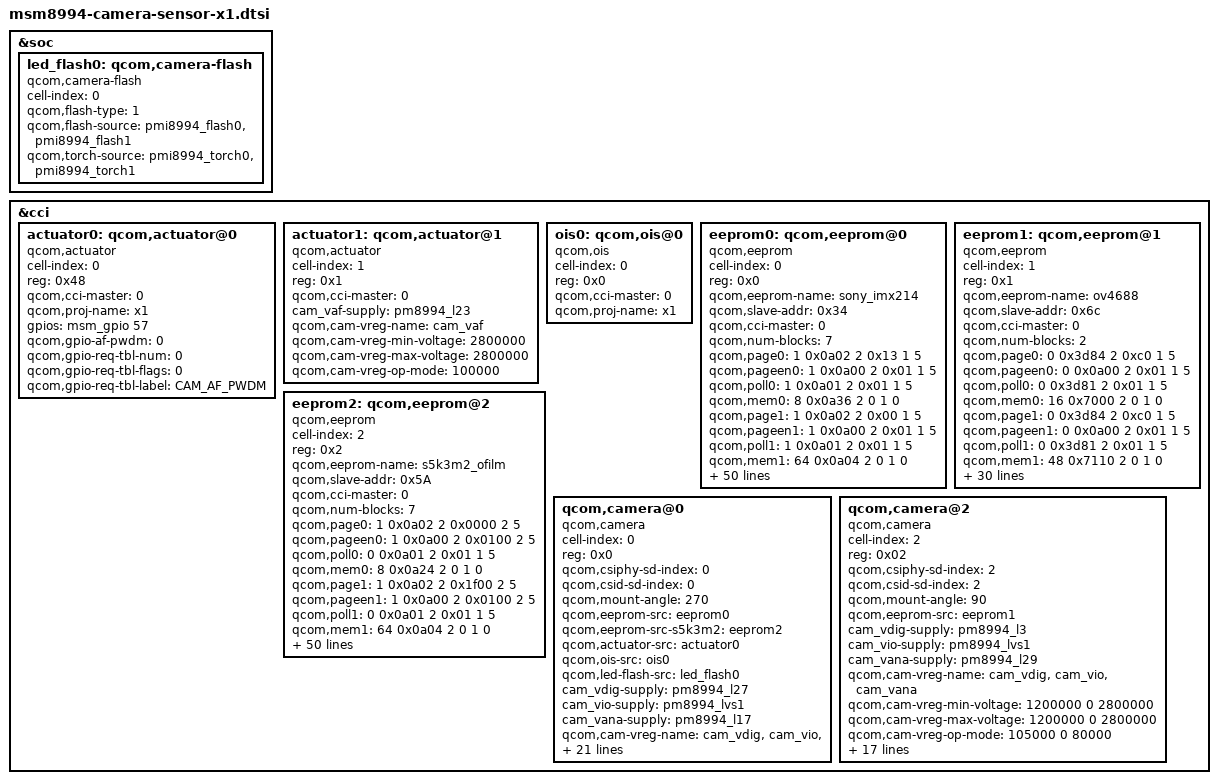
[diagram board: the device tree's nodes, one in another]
/*
 * Copyright (c) 2014, The Linux Foundation. All rights reserved.
 *
 * This program is free software; you can redistribute it and/or modify
 * it under the terms of the GNU General Public License version 2 and
 * only version 2 as published by the Free Software Foundation.
 *
 * This program is distributed in the hope that it will be useful,
 * but WITHOUT ANY WARRANTY; without even the implied warranty of
 * MERCHANTABILITY or FITNESS FOR A PARTICULAR PURPOSE.  See the
 * GNU General Public License for more details.
 */

&soc {
	led_flash0: qcom,camera-flash {
		cell-index = <0>;
		compatible = "qcom,camera-flash";
		qcom,flash-type = <1>;
		qcom,flash-source = <&pmi8994_flash0 &pmi8994_flash1>;
		qcom,torch-source = <&pmi8994_torch0 &pmi8994_torch1>;
	};
};

&cci {
	actuator0: qcom,actuator@0 {
		cell-index = <0>;
		reg = <0x48>;
		compatible = "qcom,actuator";
		qcom,cci-master = <0>;
		qcom,proj-name = "x1";
		gpios = <&msm_gpio 57 0>;
		qcom,gpio-af-pwdm = <0>;
		qcom,gpio-req-tbl-num = <0>;
		qcom,gpio-req-tbl-flags = <0>;
		qcom,gpio-req-tbl-label =  "CAM_AF_PWDM";
	};

	actuator1: qcom,actuator@1 {
		cell-index = <1>;
		reg = <0x1>;
		compatible = "qcom,actuator";
		qcom,cci-master = <0>;
		cam_vaf-supply = <&pm8994_l23>;
		qcom,cam-vreg-name = "cam_vaf";
		qcom,cam-vreg-min-voltage = <2800000>;
		qcom,cam-vreg-max-voltage = <2800000>;
		qcom,cam-vreg-op-mode = <100000>;
	};


	ois0: qcom,ois@0 {
		cell-index = <0>;
		reg = <0x0>;
		compatible = "qcom,ois";
		qcom,cci-master = <0>;
		qcom,proj-name = "x1";
		/*
		cam_vaf-supply = <&pm8994_l23>;
		qcom,cam-vreg-name = "cam_vaf";
		qcom,cam-vreg-min-voltage = <2800000>;
		qcom,cam-vreg-max-voltage = <2800000>;
		qcom,cam-vreg-op-mode = <100000>;
		*/
	};

	eeprom0: qcom,eeprom@0 {
		cell-index = <0>;
		reg = <0x0>;
		qcom,eeprom-name = "sony_imx214";
		compatible = "qcom,eeprom";
		qcom,slave-addr = <0x34>;
		qcom,cci-master = <0>;
		qcom,num-blocks = <7>;
		qcom,page0 = <1 0x0a02 2 0x13 1 5>;
		qcom,pageen0 = <1 0x0a00 2 0x01 1 5>;
		qcom,poll0 = <1 0x0a01 2 0x01 1 5>;
		qcom,mem0 = <8 0x0a36 2 0 1 0>;

		qcom,page1 = <1 0x0a02 2 0x00 1 5>;
		qcom,pageen1 = <1 0x0a00 2 0x01 1 5>;
		qcom,poll1 = <1 0x0a01 2 0x01 1 5>;
		qcom,mem1 = <64 0x0a04 2 0 1 0>;

		qcom,page2 = <1 0x0a02 2 0x01 1 5>;
		qcom,pageen2 = <1 0x0a00 2 0x01 1 5>;
		qcom,poll2 = <1 0x0a01 2 0x01 1 5>;
		qcom,mem2 = <64 0x0a04 2 0 1 0>;

		qcom,page3 = <1 0x0a02 2 0x02 1 5>;
		qcom,pageen3 = <1 0x0a00 2 0x01 1 5>;
		qcom,poll3 = <1 0x0a01 2 0x01 1 5>;
		qcom,mem3 = <64 0x0a04 2 0 1 0>;

		qcom,page4 = <1 0x0a02 2 0x03 1 5>;
		qcom,pageen4 = <1 0x0a00 2 0x01 1 5>;
		qcom,poll4 = <1 0x0a01 2 0x01 1 5>;
		qcom,mem4 = <64 0x0a04 2 0 1 0>;

		qcom,page5 = <1 0x0a02 2 0x04 1 5>;
		qcom,pageen5 = <1 0x0a00 2 0x01 1 5>;
		qcom,poll5 = <1 0x0a01 2 0x01 1 5>;
		qcom,mem5 = <64 0x0a04 2 0 1 0>;

		qcom,page6 = <1 0x0a02 2 0x6 1 5>;
		qcom,pageen6 = <1 0x0a00 2 0x01 1 5>;
		qcom,poll6 = <1 0x0a01 2 0x01 1 5>;
		qcom,mem6 = <1 0x0a04 2 0 1 0>;

		cam_vdig-supply = <&pm8994_l27>;
		cam_vio-supply = <&pm8994_lvs1>;
		cam_vana-supply = <&pm8994_l17>;
		qcom,cam-vreg-name = "cam_vdig", "cam_vio", "cam_vana";
		qcom,cam-vreg-min-voltage = <1050000 0 2700000>;
		qcom,cam-vreg-max-voltage = <1050000 0 2700000>;
		qcom,cam-vreg-op-mode = <105000 0 80000>;
		qcom,gpio-no-mux = <0>;
		pinctrl-names = "cam_default", "cam_suspend";
		pinctrl-0 = <&cam_sensor_mclk0_active &cam_sensor_rear_active>;
		pinctrl-1 = <&cam_sensor_mclk0_suspend &cam_sensor_rear_suspend>;
		gpios = <&msm_gpio 13 0>,
			<&msm_gpio 92 0>,
			<&msm_gpio 91 0>;
		qcom,gpio-reset = <1>;
		qcom,gpio-standby = <2>;
		qcom,gpio-req-tbl-num = <0 1 2>;
		qcom,gpio-req-tbl-flags = <1 0 0>;
		qcom,gpio-req-tbl-label = "CAMIF_MCLK0",
					  "CAM_RESET0",
					  "CAM_STANDBY0";
		qcom,cam-power-seq-type = "sensor_vreg", "sensor_vreg", "sensor_vreg",
			"sensor_gpio", "sensor_gpio" , "sensor_clk";
		qcom,cam-power-seq-val = "cam_vdig", "cam_vana", "cam_vio",
			"sensor_gpio_reset", "sensor_gpio_standby","sensor_cam_mclk";
		qcom,cam-power-seq-cfg-val = <1 1 1 1 1 24000000>;
		qcom,cam-power-seq-delay = <1 1 1 30 30 5>;
		status = "ok";
		clocks = <&clock_mmss clk_mclk0_clk_src>,
				<&clock_mmss clk_camss_mclk0_clk>;
		clock-names = "cam_src_clk", "cam_clk";
	};

	eeprom1: qcom,eeprom@1 {
		cell-index = <1>;
		reg = <0x1>;
		qcom,eeprom-name = "ov4688";
		compatible = "qcom,eeprom";
		qcom,slave-addr = <0x6c>;
		qcom,cci-master = <0>;
		qcom,num-blocks = <2>;

		qcom,page0 = <0 0x3d84 2 0xc0 1 5>;
		qcom,pageen0 = <0 0x0a00 2 0x01 1 5>;
		qcom,poll0 = <0 0x3d81 2 0x01 1 5>;
		qcom,mem0 = <16 0x7000 2 0 1 0>;

		qcom,page1 = <0 0x3d84 2 0xc0 1 5>;
		qcom,pageen1 = <0 0x0a00 2 0x01 1 5>;
		qcom,poll1 = <0 0x3d81 2 0x01 1 5>;
		qcom,mem1 = <48 0x7110 2 0 1 0>;

		cam_vdig-supply = <&pm8994_l3>;
		cam_vio-supply = <&pm8994_lvs1>;
		cam_vana-supply = <&pm8994_l29>;
		qcom,cam-vreg-name = "cam_vdig", "cam_vio", "cam_vana";
		qcom,cam-vreg-min-voltage = <1200000 0 2800000>;
		qcom,cam-vreg-max-voltage = <1200000 0 2800000>;
		qcom,cam-vreg-op-mode = <105000 0 80000>;
		qcom,gpio-no-mux = <0>;
		pinctrl-names = "cam_default", "cam_suspend";
		pinctrl-0 = <&cam_sensor_mclk2_active &cam_sensor_front_active>;
		pinctrl-1 = <&cam_sensor_mclk2_suspend &cam_sensor_front_suspend>;
		gpios = <&msm_gpio 15 0>,
			<&msm_gpio 104 0>,
			<&msm_gpio 105 0>;
		qcom,gpio-reset = <1>;
		qcom,gpio-standby = <2>;
		qcom,gpio-req-tbl-num = <0 1 2>;
		qcom,gpio-req-tbl-flags = <1 0 0>;
		qcom,gpio-req-tbl-label = "CAMIF_MCLK2",
					  "CAM_RESET2",
					  "CAM_STANDBY2";
		qcom,cam-power-seq-type = "sensor_vreg", "sensor_vreg", "sensor_vreg",
			"sensor_gpio", "sensor_gpio" , "sensor_clk";
		qcom,cam-power-seq-val = "cam_vdig", "cam_vana", "cam_vio",
			"sensor_gpio_reset", "sensor_gpio_standby","sensor_cam_mclk";
		qcom,cam-power-seq-cfg-val = <1 1 1 1 1 24000000>;
		qcom,cam-power-seq-delay = <1 1 1 30 30 5>;
		status = "ok";
		clocks = <&clock_mmss clk_mclk2_clk_src>,
				<&clock_mmss clk_camss_mclk2_clk>;
		clock-names = "cam_src_clk", "cam_clk";
	};

	/* ADD-S 20150512 EEPROM for s5k3m2-ofilm */
	eeprom2: qcom,eeprom@2 {
		cell-index = <2>;
		reg = <0x2>;
		qcom,eeprom-name = "s5k3m2_ofilm";
		compatible = "qcom,eeprom";
		qcom,slave-addr = <0x5A>;
		qcom,cci-master = <0>;
		qcom,num-blocks = <7>;
		qcom,page0 = <1 0x0a02 2 0x0000 2 5>;
		qcom,pageen0 = <1 0x0a00 2 0x0100 2 5>;
		qcom,poll0 = <0 0x0a01 2 0x01 1 5>;
		qcom,mem0 = <8 0x0a24 2 0 1 0>;

		qcom,page1 = <1 0x0a02 2 0x1f00 2 5>;
		qcom,pageen1 = <1 0x0a00 2 0x0100 2 5>;
		qcom,poll1 = <0 0x0a01 2 0x01 1 5>;
		qcom,mem1 = <64 0x0a04 2 0 1 0>;

		qcom,page2 = <1 0x0a02 2 0x0100 2 5>;
		qcom,pageen2 = <1 0x0a00 2 0x0100 2 5>;
		qcom,poll2 = <0 0x0a01 2 0x01 1 5>;
		qcom,mem2 = <64 0x0a04 2 0 1 0>;

		qcom,page3 = <1 0x0a02 2 0x0200 2 5>;
		qcom,pageen3 = <1 0x0a00 2 0x0100 2 5>;
		qcom,poll3 = <0 0x0a01 2 0x01 1 5>;
		qcom,mem3 = <64 0x0a04 2 0 1 0>;

		qcom,page4 = <1 0x0a02 2 0x0300 2 5>;
		qcom,pageen4 = <1 0x0a00 2 0x0100 2 5>;
		qcom,poll4 = <0 0x0a01 2 0x01 1 5>;
		qcom,mem4 = <64 0x0a04 2 0 1 0>;

		qcom,page5 = <1 0x0a02 2 0x0400 2 5>;
		qcom,pageen5 = <1 0x0a00 2 0x0100 2 5>;
		qcom,poll5 = <0 0x0a01 2 0x01 1 5>;
		qcom,mem5 = <64 0x0a04 2 0 1 0>;


		qcom,page6 = <1 0x0a02 2 0x0600 2 5>;
		qcom,pageen6 = <1 0x0a00 2 0x0100 2 5>;
		qcom,poll6 = <0 0x0a01 2 0x01 1 5>;
		qcom,mem6 = <1 0x0a04 2 0 1 0>;

		cam_vdig-supply = <&pm8994_l27>;
		cam_vio-supply = <&pm8994_lvs1>;
		cam_vana-supply = <&pm8994_l17>;
		qcom,cam-vreg-name = "cam_vdig", "cam_vio", "cam_vana";
		qcom,cam-vreg-min-voltage = <1050000 0 2700000>;
		qcom,cam-vreg-max-voltage = <1050000 0 2700000>;
		qcom,cam-vreg-op-mode = <105000 0 80000>;
		qcom,gpio-no-mux = <0>;
		pinctrl-names = "cam_default", "cam_suspend";
		pinctrl-0 = <&cam_sensor_mclk0_active &cam_sensor_rear_active>;
		pinctrl-1 = <&cam_sensor_mclk0_suspend &cam_sensor_rear_suspend>;
		gpios = <&msm_gpio 13 0>,
			<&msm_gpio 92 0>,
			<&msm_gpio 91 0>;
		qcom,gpio-reset = <1>;
		qcom,gpio-standby = <2>;
		qcom,gpio-req-tbl-num = <0 1 2>;
		qcom,gpio-req-tbl-flags = <1 0 0>;
		qcom,gpio-req-tbl-label = "CAMIF_MCLK0",
					  "CAM_RESET0",
					  "CAM_STANDBY0";
		qcom,cam-power-seq-type = "sensor_vreg", "sensor_vreg", "sensor_vreg",
			"sensor_gpio", "sensor_gpio" , "sensor_clk";
		qcom,cam-power-seq-val = "cam_vdig", "cam_vana", "cam_vio",
			"sensor_gpio_reset", "sensor_gpio_standby","sensor_cam_mclk";
		qcom,cam-power-seq-cfg-val = <1 1 1 1 1 24000000>;
		qcom,cam-power-seq-delay = <1 1 1 30 30 5>;
		status = "ok";
		clocks = <&clock_mmss clk_mclk0_clk_src>,
				<&clock_mmss clk_camss_mclk0_clk>;
		clock-names = "cam_src_clk", "cam_clk";
	};
	/* ADD-E 20150512 EEPROM for s5k3m2-ofilm */

	qcom,camera@0 {
		cell-index = <0>;
		compatible = "qcom,camera";
		reg = <0x0>;
		qcom,csiphy-sd-index = <0>;
		qcom,csid-sd-index = <0>;
		qcom,mount-angle = <270>;
		qcom,eeprom-src = <&eeprom0>;
		/* ADD-S 20150512 EEPROM for s5k3m2-ofilm */
		qcom,eeprom-src-s5k3m2 = <&eeprom2>;
		/* ADD-E 20150512 EEPROM for s5k3m2-ofilm */
		qcom,actuator-src = <&actuator0>;
		qcom,ois-src = <&ois0>;
		qcom,led-flash-src = <&led_flash0>;
		cam_vdig-supply = <&pm8994_l27>;
		cam_vio-supply = <&pm8994_lvs1>;
		cam_vana-supply = <&pm8994_l17>;
		qcom,cam-vreg-name = "cam_vdig", "cam_vio", "cam_vana";
		qcom,cam-vreg-min-voltage = <1050000 0 2700000>;
		qcom,cam-vreg-max-voltage = <1050000 0 2700000>;
		qcom,cam-vreg-op-mode = <105000 0 80000>;
		qcom,gpio-no-mux = <0>;
		pinctrl-names = "cam_default", "cam_suspend";
		pinctrl-0 = <&cam_sensor_mclk0_active &cam_sensor_rear_active>;
		pinctrl-1 = <&cam_sensor_mclk0_suspend &cam_sensor_rear_suspend>;
		gpios = <&msm_gpio 13 0>,
			<&msm_gpio 57 0>,
			<&msm_gpio 91 0>;
		qcom,gpio-vaf = <1>;
		qcom,gpio-standby = <2>;
		qcom,gpio-req-tbl-num = <0 1 2>;
		qcom,gpio-req-tbl-flags = <1 0 0>;
		qcom,gpio-req-tbl-label = "CAMIF_MCLK0",
					  "CAM_AF0",
					  "CAM_STANDBY0";
		qcom,sensor-position = <0>;
		qcom,sensor-mode = <0>;
		qcom,cci-master = <0>;
		status = "ok";
		clocks = <&clock_mmss clk_mclk0_clk_src>,
				<&clock_mmss clk_camss_mclk0_clk>;
		clock-names = "cam_src_clk", "cam_clk";
	};
/*
	qcom,camera@1 {
		cell-index = <1>;
		compatible = "qcom,camera";
		reg = <0x1>;
		qcom,csiphy-sd-index = <1>;
		qcom,csid-sd-index = <1>;
		qcom,mount-angle = <90>;
		cam_vdig-supply = <&pm8994_l3>;
		cam_vio-supply = <&pm8994_lvs1>;
		cam_vana-supply = <&pm8994_l17>;
		qcom,cam-vreg-name = "cam_vdig", "cam_vio", "cam_vana";
		qcom,cam-vreg-min-voltage = <1200000 0 2700000>;
		qcom,cam-vreg-max-voltage = <1200000 0 2700000>;
		qcom,cam-vreg-op-mode = <105000 0 80000>;
		qcom,gpio-no-mux = <0>;
		pinctrl-names = "cam_default", "cam_suspend";
		pinctrl-0 = <&cam_sensor_mclk1_active &cam_sensor_rear2_active>;
		pinctrl-1 = <&cam_sensor_mclk1_suspend &cam_sensor_rear2_suspend>;
		gpios = <&msm_gpio 14 0>,
			<&msm_gpio 94 0>,
			<&msm_gpio 93 0>;
		qcom,gpio-reset = <1>;
		qcom,gpio-standby = <2>;
		qcom,gpio-req-tbl-num = <0 1 2>;
		qcom,gpio-req-tbl-flags = <1 0 0>;
		qcom,gpio-req-tbl-label = "CAMIF_MCLK1",
					  "CAM_RESET1",
					  "CAM_STANDBY1";
		qcom,sensor-position = <0>;
		qcom,sensor-mode = <0>;
		qcom,cci-master = <0>;
		status = "disabled";
		clocks = <&clock_mmss clk_mclk1_clk_src>,
			<&clock_mmss clk_camss_mclk1_clk>;
		clock-names = "cam_src_clk", "cam_clk";
	};
*/
	qcom,camera@2 {
		cell-index = <2>;
		compatible = "qcom,camera";
		reg = <0x02>;
		qcom,csiphy-sd-index = <2>;
		qcom,csid-sd-index = <2>;
		qcom,mount-angle = <90>;
		qcom,eeprom-src = <&eeprom1>;
		cam_vdig-supply = <&pm8994_l3>;
		cam_vio-supply = <&pm8994_lvs1>;
		cam_vana-supply = <&pm8994_l29>;
		qcom,cam-vreg-name = "cam_vdig", "cam_vio", "cam_vana";
		qcom,cam-vreg-min-voltage = <1200000 0 2800000>;
		qcom,cam-vreg-max-voltage = <1200000 0 2800000>;
		qcom,cam-vreg-op-mode = <105000 0 80000>;
		qcom,gpio-no-mux = <0>;
		pinctrl-names = "cam_default", "cam_suspend";
		pinctrl-0 = <&cam_sensor_mclk2_active &cam_sensor_front_active>;
		pinctrl-1 = <&cam_sensor_mclk2_suspend &cam_sensor_front_suspend>;
		gpios = <&msm_gpio 15 0>,
			<&msm_gpio 104 0>,
			<&msm_gpio 105 0>;
		qcom,gpio-reset = <1>;
		qcom,gpio-standby = <2>;
		qcom,gpio-req-tbl-num = <0 1 2>;
		qcom,gpio-req-tbl-flags = <1 0 0>;
		qcom,gpio-req-tbl-label = "CAMIF_MCLK2",
					  "CAM_RESET2",
					  "CAM_STANDBY2";
		qcom,sensor-position = <1>;
		qcom,sensor-mode = <0>;
		qcom,cci-master = <0>;
		status = "ok";
		clocks = <&clock_mmss clk_mclk2_clk_src>,
			<&clock_mmss clk_camss_mclk2_clk>;
		clock-names = "cam_src_clk", "cam_clk";
	};
};
